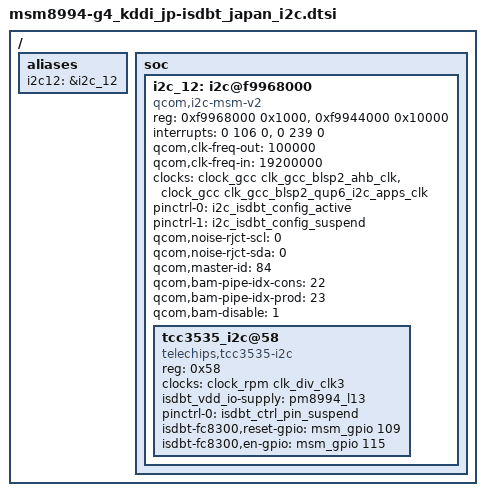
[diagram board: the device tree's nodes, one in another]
/* Copyright (c) 2014, The Linux Foundation. All rights reserved.
 *
 * This program is free software; you can redistribute it and/or modify
 * it under the terms of the GNU General Public License version 2 and
 * only version 2 as published by the Free Software Foundation.
 *
 * This program is distributed in the hope that it will be useful,
 * but WITHOUT ANY WARRANTY; without even the implied warranty of
 * MERCHANTABILITY or FITNESS FOR A PARTICULAR PURPOSE.  See the
 * GNU General Public License for more details.
 */
/ {
	aliases {
		i2c12 = &i2c_12;
	};
	soc {
		i2c_12:i2c@f9968000{ /* BLSP12, BLSP-2 QUP-5 */
			compatible = "qcom,i2c-msm-v2";
			#address-cells = <1>;
			#size-cells = <0>;

			reg-names = "qup_phys_addr", "bam_phys_addr";
			reg = <0xf9968000 0x1000>,
				  <0xf9944000 0x10000>;

			interrupt-names = "qup_irq", "bam_irq";
			interrupts = <0 106 0>, <0 239 0>;

			qcom,clk-freq-out = <100000>; // Output clock frequency (can be up to 3400000)
			qcom,clk-freq-in = <19200000>;
			clock-names = "iface_clk", "core_clk"; // Setup Fabric and core clocks
			clocks = <&clock_gcc clk_gcc_blsp2_ahb_clk>, <&clock_gcc clk_gcc_blsp2_qup6_i2c_apps_clk>;

			pinctrl-names = "i2c_active", "i2c_sleep"; // pin functions
			pinctrl-0 = <&i2c_isdbt_config_active>; // defined in msm8994-pinctrl.dtsi
			pinctrl-1 = <&i2c_isdbt_config_suspend>; // defined in msm8994-pinctrl.dtsi
			qcom,noise-rjct-scl = <0>; // For noise dectection over SCL
			qcom,noise-rjct-sda = <0>; // For noise dectection over SDC
			qcom,master-id = <84>;
			qcom,bam-pipe-idx-cons = <22>;
			qcom,bam-pipe-idx-prod = <23>;
			qcom,bam-disable= <1>; /* BAM mode disable */
		};
	};
};
&i2c_12 {
	tcc3535_i2c@58 {
		compatible = "telechips,tcc3535-i2c";
		reg = <0x58>;

		clock-names = "isdbt_xo";
		clocks = <&clock_rpm clk_div_clk3>;

		isdbt_vdd_io-supply = <&pm8994_l13>;

		pinctrl-names = "isdbt_gpio_suspend";
		pinctrl-0 = <&isdbt_ctrl_pin_suspend>;
		isdbt-fc8300,reset-gpio = <&msm_gpio 109 0x00>;
		isdbt-fc8300,en-gpio = <&msm_gpio 115 0x00>;
	};
};
